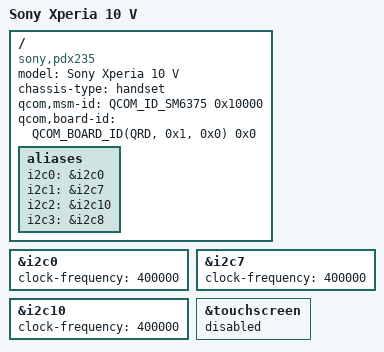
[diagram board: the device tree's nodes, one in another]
// SPDX-License-Identifier: BSD-3-Clause
/*
 * Copyright (c) 2023, Konrad Dybcio <konrad.dybcio@linaro.org>
 */

/dts-v1/;

#include <dt-bindings/arm/qcom,ids.h>

#include "sm6375-sony-xperia-murray.dtsi"

/ {
	model = "Sony Xperia 10 V";
	compatible = "sony,pdx235", "qcom,sm6375";
	chassis-type = "handset";
	qcom,msm-id = <QCOM_ID_SM6375 0x10000>;
	qcom,board-id = <QCOM_BOARD_ID(QRD, 0x1, 0x0) 0x0>;

	aliases {
		i2c0 = &i2c0;
		i2c1 = &i2c7;
		i2c2 = &i2c10;
		i2c3 = &i2c8;
	};
};

&i2c0 {
	clock-frequency = <400000>;
	status = "okay";

	/* NXP SN2x0 NFC @ 28. (or on &spi2.. TBD!) */
};

&i2c7 {
	clock-frequency = <400000>;
	status = "okay";

	/* Awinic AW882xx audio amplifier ("channel 0") @ 34 */
};

/* I2C8 inherited from common DTSI */

&i2c10 {
	clock-frequency = <400000>;
	status = "okay";

	/* Awinic AW882xx audio amplifier ("channel 1") @ 34 */
	/* PM8008 @ 8, 9 */
};

/* For reasons yet unknown, it's broken on the mark V.. */
&touchscreen {
	status = "fail";
};
